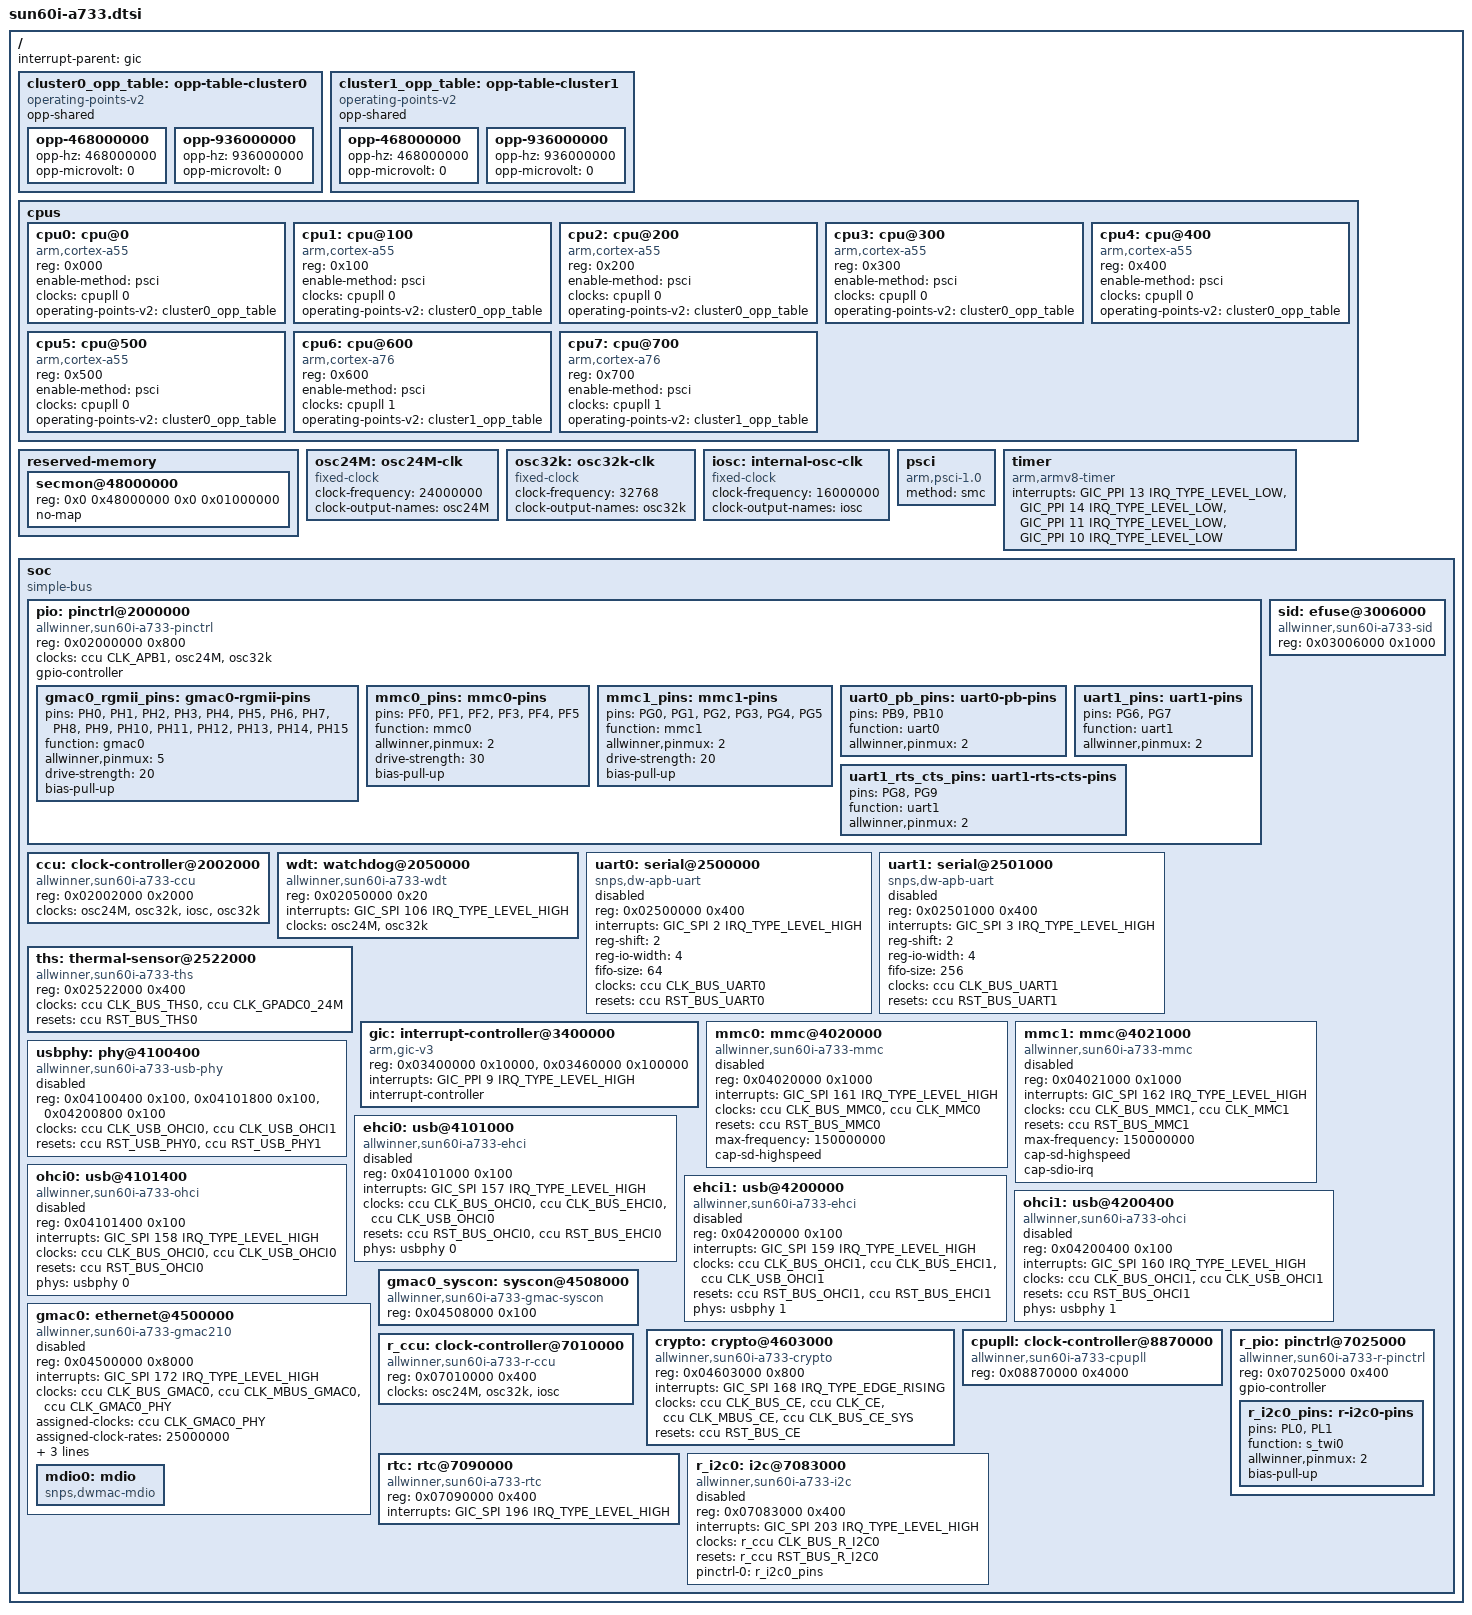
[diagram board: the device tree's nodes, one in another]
// SPDX-License-Identifier: (GPL-2.0-only OR MIT)
/*
 * Allwinner A733 (sun60iw2).
 *
 * Addresses and interrupt numbers were checked against the vendor kernel
 * tree and, where a register could be read, on an Orange Pi Zero 4.
 */

#include <dt-bindings/interrupt-controller/arm-gic.h>
#include <dt-bindings/clock/allwinner,sun60i-a733-ccu.h>
#include <dt-bindings/clock/allwinner,sun60i-a733-r-ccu.h>
#include <dt-bindings/reset/allwinner,sun60i-a733-ccu.h>
#include <dt-bindings/reset/allwinner,sun60i-a733-r-ccu.h>

/ {
	interrupt-parent = <&gic>;
	#address-cells = <2>;
	#size-cells = <2>;

	/*
	 * What the divider behind each cluster's PLL offers at the PLL rate
	 * and the supply voltage the boot loader leaves. No regulator is
	 * described, so the voltages are placeholders.
	 */
	cluster0_opp_table: opp-table-cluster0 {
		compatible = "operating-points-v2";
		opp-shared;

		opp-468000000 {
			opp-hz = /bits/ 64 <468000000>;
			opp-microvolt = <0>;
		};

		opp-936000000 {
			opp-hz = /bits/ 64 <936000000>;
			opp-microvolt = <0>;
		};
	};

	cluster1_opp_table: opp-table-cluster1 {
		compatible = "operating-points-v2";
		opp-shared;

		opp-468000000 {
			opp-hz = /bits/ 64 <468000000>;
			opp-microvolt = <0>;
		};

		opp-936000000 {
			opp-hz = /bits/ 64 <936000000>;
			opp-microvolt = <0>;
		};
	};

	cpus {
		#address-cells = <1>;
		#size-cells = <0>;

		cpu0: cpu@0 {
			compatible = "arm,cortex-a55";
			device_type = "cpu";
			reg = <0x000>;
			enable-method = "psci";
			clocks = <&cpupll 0>;
			operating-points-v2 = <&cluster0_opp_table>;
		};

		cpu1: cpu@100 {
			compatible = "arm,cortex-a55";
			device_type = "cpu";
			reg = <0x100>;
			enable-method = "psci";
			clocks = <&cpupll 0>;
			operating-points-v2 = <&cluster0_opp_table>;
		};

		cpu2: cpu@200 {
			compatible = "arm,cortex-a55";
			device_type = "cpu";
			reg = <0x200>;
			enable-method = "psci";
			clocks = <&cpupll 0>;
			operating-points-v2 = <&cluster0_opp_table>;
		};

		cpu3: cpu@300 {
			compatible = "arm,cortex-a55";
			device_type = "cpu";
			reg = <0x300>;
			enable-method = "psci";
			clocks = <&cpupll 0>;
			operating-points-v2 = <&cluster0_opp_table>;
		};

		cpu4: cpu@400 {
			compatible = "arm,cortex-a55";
			device_type = "cpu";
			reg = <0x400>;
			enable-method = "psci";
			clocks = <&cpupll 0>;
			operating-points-v2 = <&cluster0_opp_table>;
		};

		cpu5: cpu@500 {
			compatible = "arm,cortex-a55";
			device_type = "cpu";
			reg = <0x500>;
			enable-method = "psci";
			clocks = <&cpupll 0>;
			operating-points-v2 = <&cluster0_opp_table>;
		};

		cpu6: cpu@600 {
			compatible = "arm,cortex-a76";
			device_type = "cpu";
			reg = <0x600>;
			enable-method = "psci";
			clocks = <&cpupll 1>;
			operating-points-v2 = <&cluster1_opp_table>;
		};

		cpu7: cpu@700 {
			compatible = "arm,cortex-a76";
			device_type = "cpu";
			reg = <0x700>;
			enable-method = "psci";
			clocks = <&cpupll 1>;
			operating-points-v2 = <&cluster1_opp_table>;
		};
	};

	reserved-memory {
		#address-cells = <2>;
		#size-cells = <2>;
		ranges;

		/* EL3 monitor (BL31) */
		secmon@48000000 {
			reg = <0x0 0x48000000 0x0 0x01000000>;
			no-map;
		};
	};

	osc24M: osc24M-clk {
		#clock-cells = <0>;
		compatible = "fixed-clock";
		clock-frequency = <24000000>;
		clock-output-names = "osc24M";
	};

	osc32k: osc32k-clk {
		#clock-cells = <0>;
		compatible = "fixed-clock";
		clock-frequency = <32768>;
		clock-output-names = "osc32k";
	};

	iosc: internal-osc-clk {
		#clock-cells = <0>;
		compatible = "fixed-clock";
		clock-frequency = <16000000>;
		clock-output-names = "iosc";
	};

	psci {
		compatible = "arm,psci-1.0";
		method = "smc";
	};

	timer {
		compatible = "arm,armv8-timer";
		interrupts = <GIC_PPI 13 IRQ_TYPE_LEVEL_LOW>,
			     <GIC_PPI 14 IRQ_TYPE_LEVEL_LOW>,
			     <GIC_PPI 11 IRQ_TYPE_LEVEL_LOW>,
			     <GIC_PPI 10 IRQ_TYPE_LEVEL_LOW>;
	};

	soc {
		compatible = "simple-bus";
		#address-cells = <1>;
		#size-cells = <1>;
		ranges = <0x0 0x0 0x0 0x40000000>;

		pio: pinctrl@2000000 {
			compatible = "allwinner,sun60i-a733-pinctrl";
			reg = <0x02000000 0x800>;
			clocks = <&ccu CLK_APB1>, <&osc24M>, <&osc32k>;
			clock-names = "apb", "hosc", "losc";
			gpio-controller;
			#gpio-cells = <3>;

			gmac0_rgmii_pins: gmac0-rgmii-pins {
				pins = "PH0", "PH1", "PH2", "PH3",
				       "PH4", "PH5", "PH6", "PH7",
				       "PH8", "PH9", "PH10", "PH11",
				       "PH12", "PH13", "PH14", "PH15";
				function = "gmac0";
				allwinner,pinmux = <5>;
				drive-strength = <20>;
				bias-pull-up;
			};

			mmc0_pins: mmc0-pins {
				pins = "PF0", "PF1", "PF2", "PF3", "PF4", "PF5";
				function = "mmc0";
				allwinner,pinmux = <2>;
				drive-strength = <30>;
				bias-pull-up;
			};

			mmc1_pins: mmc1-pins {
				pins = "PG0", "PG1", "PG2", "PG3", "PG4", "PG5";
				function = "mmc1";
				allwinner,pinmux = <2>;
				drive-strength = <20>;
				bias-pull-up;
			};

			uart0_pb_pins: uart0-pb-pins {
				pins = "PB9", "PB10";
				function = "uart0";
				allwinner,pinmux = <2>;
			};

			uart1_pins: uart1-pins {
				pins = "PG6", "PG7";
				function = "uart1";
				allwinner,pinmux = <2>;
			};

			uart1_rts_cts_pins: uart1-rts-cts-pins {
				pins = "PG8", "PG9";
				function = "uart1";
				allwinner,pinmux = <2>;
			};
		};

		ccu: clock-controller@2002000 {
			compatible = "allwinner,sun60i-a733-ccu";
			reg = <0x02002000 0x2000>;
			clocks = <&osc24M>, <&osc32k>, <&iosc>, <&osc32k>;
			clock-names = "hosc", "losc", "iosc", "losc-fanout";
			#clock-cells = <1>;
			#reset-cells = <1>;
		};

		/* The same register layout as on the A523. */
		wdt: watchdog@2050000 {
			compatible = "allwinner,sun60i-a733-wdt",
				     "allwinner,sun55i-a523-wdt";
			reg = <0x02050000 0x20>;
			interrupts = <GIC_SPI 106 IRQ_TYPE_LEVEL_HIGH>;
			clocks = <&osc24M>, <&osc32k>;
			clock-names = "hosc", "losc";
		};

		uart0: serial@2500000 {
			compatible = "snps,dw-apb-uart";
			reg = <0x02500000 0x400>;
			interrupts = <GIC_SPI 2 IRQ_TYPE_LEVEL_HIGH>;
			reg-shift = <2>;
			reg-io-width = <4>;
			fifo-size = <64>;
			clocks = <&ccu CLK_BUS_UART0>;
			resets = <&ccu RST_BUS_UART0>;
			status = "disabled";
		};

		uart1: serial@2501000 {
			compatible = "snps,dw-apb-uart";
			reg = <0x02501000 0x400>;
			interrupts = <GIC_SPI 3 IRQ_TYPE_LEVEL_HIGH>;
			reg-shift = <2>;
			reg-io-width = <4>;
			fifo-size = <256>;
			clocks = <&ccu CLK_BUS_UART1>;
			resets = <&ccu RST_BUS_UART1>;
			status = "disabled";
		};

		/* Not an upstream binding yet. */
		ths: thermal-sensor@2522000 {
			compatible = "allwinner,sun60i-a733-ths";
			reg = <0x02522000 0x400>;
			clocks = <&ccu CLK_BUS_THS0>, <&ccu CLK_GPADC0_24M>;
			clock-names = "bus", "gpadc";
			resets = <&ccu RST_BUS_THS0>;
			#thermal-sensor-cells = <1>;
		};

		/* Not an upstream binding yet. */
		sid: efuse@3006000 {
			compatible = "allwinner,sun60i-a733-sid";
			reg = <0x03006000 0x1000>;
		};

		gic: interrupt-controller@3400000 {
			compatible = "arm,gic-v3";
			reg = <0x03400000 0x10000>,
			      <0x03460000 0x100000>;
			interrupts = <GIC_PPI 9 IRQ_TYPE_LEVEL_HIGH>;
			interrupt-controller;
			#interrupt-cells = <3>;
		};

		mmc0: mmc@4020000 {
			compatible = "allwinner,sun60i-a733-mmc",
				     "allwinner,sun20i-d1-mmc";
			reg = <0x04020000 0x1000>;
			interrupts = <GIC_SPI 161 IRQ_TYPE_LEVEL_HIGH>;
			clocks = <&ccu CLK_BUS_MMC0>, <&ccu CLK_MMC0>;
			clock-names = "ahb", "mmc";
			resets = <&ccu RST_BUS_MMC0>;
			reset-names = "ahb";
			max-frequency = <150000000>;
			cap-sd-highspeed;
			#address-cells = <1>;
			#size-cells = <0>;
			status = "disabled";
		};

		mmc1: mmc@4021000 {
			compatible = "allwinner,sun60i-a733-mmc",
				     "allwinner,sun20i-d1-mmc";
			reg = <0x04021000 0x1000>;
			interrupts = <GIC_SPI 162 IRQ_TYPE_LEVEL_HIGH>;
			clocks = <&ccu CLK_BUS_MMC1>, <&ccu CLK_MMC1>;
			clock-names = "ahb", "mmc";
			resets = <&ccu RST_BUS_MMC1>;
			reset-names = "ahb";
			max-frequency = <150000000>;
			cap-sd-highspeed;
			cap-sdio-irq;
			#address-cells = <1>;
			#size-cells = <0>;
			status = "disabled";
		};

		usbphy: phy@4100400 {
			compatible = "allwinner,sun60i-a733-usb-phy";
			reg = <0x04100400 0x100>,
			      <0x04101800 0x100>,
			      <0x04200800 0x100>;
			reg-names = "phy_ctrl", "pmu0", "pmu1";
			clocks = <&ccu CLK_USB_OHCI0>, <&ccu CLK_USB_OHCI1>;
			clock-names = "usb0_phy", "usb1_phy";
			resets = <&ccu RST_USB_PHY0>, <&ccu RST_USB_PHY1>;
			reset-names = "usb0_reset", "usb1_reset";
			#phy-cells = <1>;
			status = "disabled";
		};

		ehci0: usb@4101000 {
			compatible = "allwinner,sun60i-a733-ehci", "generic-ehci";
			reg = <0x04101000 0x100>;
			interrupts = <GIC_SPI 157 IRQ_TYPE_LEVEL_HIGH>;
			clocks = <&ccu CLK_BUS_OHCI0>, <&ccu CLK_BUS_EHCI0>,
				 <&ccu CLK_USB_OHCI0>;
			resets = <&ccu RST_BUS_OHCI0>, <&ccu RST_BUS_EHCI0>;
			phys = <&usbphy 0>;
			phy-names = "usb";
			status = "disabled";
		};

		ohci0: usb@4101400 {
			compatible = "allwinner,sun60i-a733-ohci", "generic-ohci";
			reg = <0x04101400 0x100>;
			interrupts = <GIC_SPI 158 IRQ_TYPE_LEVEL_HIGH>;
			clocks = <&ccu CLK_BUS_OHCI0>, <&ccu CLK_USB_OHCI0>;
			resets = <&ccu RST_BUS_OHCI0>;
			phys = <&usbphy 0>;
			phy-names = "usb";
			status = "disabled";
		};

		ehci1: usb@4200000 {
			compatible = "allwinner,sun60i-a733-ehci", "generic-ehci";
			reg = <0x04200000 0x100>;
			interrupts = <GIC_SPI 159 IRQ_TYPE_LEVEL_HIGH>;
			clocks = <&ccu CLK_BUS_OHCI1>, <&ccu CLK_BUS_EHCI1>,
				 <&ccu CLK_USB_OHCI1>;
			resets = <&ccu RST_BUS_OHCI1>, <&ccu RST_BUS_EHCI1>;
			phys = <&usbphy 1>;
			phy-names = "usb";
			status = "disabled";
		};

		ohci1: usb@4200400 {
			compatible = "allwinner,sun60i-a733-ohci", "generic-ohci";
			reg = <0x04200400 0x100>;
			interrupts = <GIC_SPI 160 IRQ_TYPE_LEVEL_HIGH>;
			clocks = <&ccu CLK_BUS_OHCI1>, <&ccu CLK_USB_OHCI1>;
			resets = <&ccu RST_BUS_OHCI1>;
			phys = <&usbphy 1>;
			phy-names = "usb";
			status = "disabled";
		};

		/*
		 * The compatible string is not an upstream binding yet;
		 * the Linux driver for the A523 calls its controller
		 * allwinner,sun55i-a523-gmac200.
		 */
		gmac0: ethernet@4500000 {
			compatible = "allwinner,sun60i-a733-gmac210";
			reg = <0x04500000 0x8000>;
			interrupts = <GIC_SPI 172 IRQ_TYPE_LEVEL_HIGH>;
			interrupt-names = "macirq";
			clocks = <&ccu CLK_BUS_GMAC0>, <&ccu CLK_MBUS_GMAC0>,
				 <&ccu CLK_GMAC0_PHY>;
			clock-names = "stmmaceth", "mbus", "phy";
			assigned-clocks = <&ccu CLK_GMAC0_PHY>;
			assigned-clock-rates = <25000000>;
			resets = <&ccu RST_BUS_GMAC0>, <&ccu RST_BUS_GMAC0_AXI>;
			reset-names = "stmmaceth", "ahb";
			syscon = <&gmac0_syscon>;
			status = "disabled";

			mdio0: mdio {
				compatible = "snps,dwmac-mdio";
				#address-cells = <1>;
				#size-cells = <0>;
			};
		};

		gmac0_syscon: syscon@4508000 {
			compatible = "allwinner,sun60i-a733-gmac-syscon",
				     "syscon";
			reg = <0x04508000 0x100>;
		};

		/* Not an upstream binding yet. */
		crypto: crypto@4603000 {
			compatible = "allwinner,sun60i-a733-crypto";
			reg = <0x04603000 0x800>;
			interrupts = <GIC_SPI 168 IRQ_TYPE_EDGE_RISING>;
			clocks = <&ccu CLK_BUS_CE>, <&ccu CLK_CE>,
				 <&ccu CLK_MBUS_CE>, <&ccu CLK_BUS_CE_SYS>;
			clock-names = "bus", "mod", "ram", "sys";
			resets = <&ccu RST_BUS_CE>;
		};

		/* Not an upstream binding yet. Clock 0: little cores, 1: big. */
		cpupll: clock-controller@8870000 {
			compatible = "allwinner,sun60i-a733-cpupll";
			reg = <0x08870000 0x4000>;
			#clock-cells = <1>;
		};

		r_ccu: clock-controller@7010000 {
			compatible = "allwinner,sun60i-a733-r-ccu";
			reg = <0x07010000 0x400>;
			clocks = <&osc24M>, <&osc32k>, <&iosc>;
			clock-names = "hosc", "losc", "iosc";
			#clock-cells = <1>;
			#reset-cells = <1>;
		};

		/* Pins of the always-on domain. */
		r_pio: pinctrl@7025000 {
			compatible = "allwinner,sun60i-a733-r-pinctrl";
			reg = <0x07025000 0x400>;
			gpio-controller;
			#gpio-cells = <3>;

			r_i2c0_pins: r-i2c0-pins {
				pins = "PL0", "PL1";
				function = "s_twi0";
				allwinner,pinmux = <2>;
				bias-pull-up;
			};
		};

		rtc: rtc@7090000 {
			compatible = "allwinner,sun60i-a733-rtc";
			reg = <0x07090000 0x400>;
			interrupts = <GIC_SPI 196 IRQ_TYPE_LEVEL_HIGH>;
		};

		r_i2c0: i2c@7083000 {
			compatible = "allwinner,sun60i-a733-i2c",
				     "allwinner,sun6i-a31-i2c";
			reg = <0x07083000 0x400>;
			interrupts = <GIC_SPI 203 IRQ_TYPE_LEVEL_HIGH>;
			clocks = <&r_ccu CLK_BUS_R_I2C0>;
			resets = <&r_ccu RST_BUS_R_I2C0>;
			pinctrl-names = "default";
			pinctrl-0 = <&r_i2c0_pins>;
			#address-cells = <1>;
			#size-cells = <0>;
			status = "disabled";
		};
	};
};
